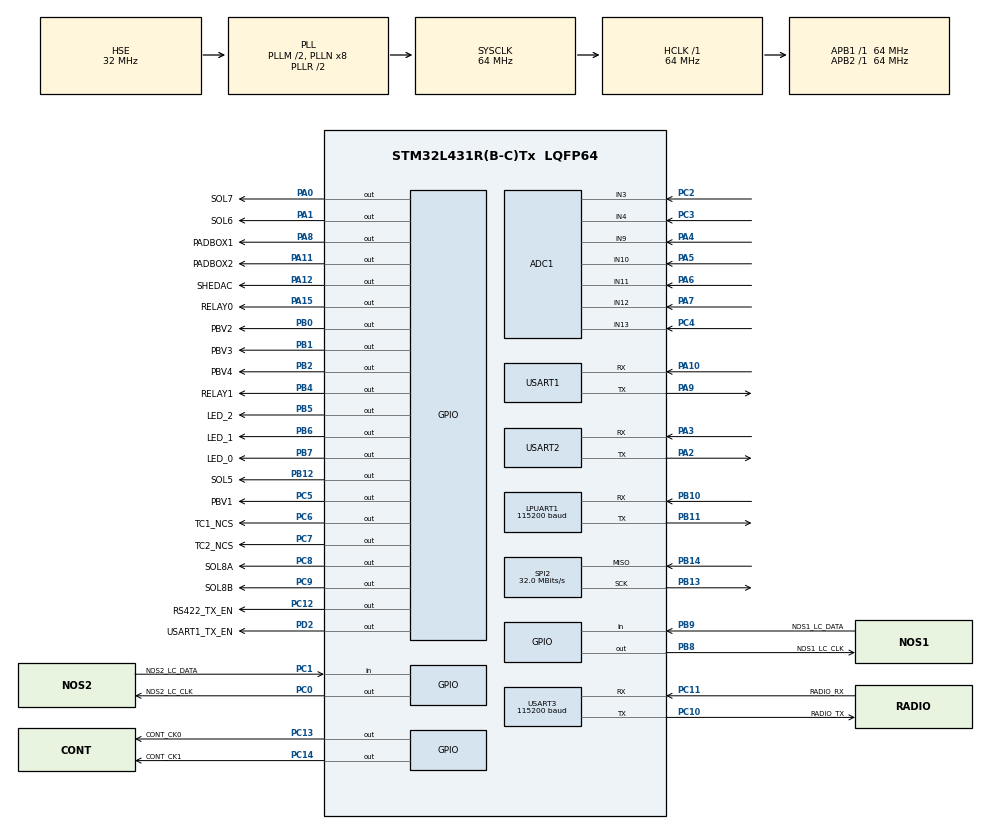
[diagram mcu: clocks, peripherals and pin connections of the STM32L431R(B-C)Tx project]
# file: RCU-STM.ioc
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ADC1.Channel-0\#ChannelRegularConversion=ADC_CHANNEL_13
ADC1.Channel-1\#ChannelRegularConversion=ADC_CHANNEL_10
ADC1.Channel-2\#ChannelRegularConversion=ADC_CHANNEL_9
ADC1.Channel-4\#ChannelRegularConversion=ADC_CHANNEL_3
ADC1.ClockPrescaler=ADC_CLOCK_ASYNC_DIV1
ADC1.ContinuousConvMode=ENABLE
ADC1.NbrOfConversion=4
ADC1.NbrOfConversionFlag=1
ADC1.OffsetNumber-0\#ChannelRegularConversion=ADC_OFFSET_NONE
ADC1.OffsetNumber-1\#ChannelRegularConversion=ADC_OFFSET_NONE
ADC1.OffsetNumber-2\#ChannelRegularConversion=ADC_OFFSET_NONE
ADC1.OffsetNumber-4\#ChannelRegularConversion=ADC_OFFSET_NONE
ADC1.Rank-0\#ChannelRegularConversion=1
ADC1.Rank-1\#ChannelRegularConversion=2
ADC1.Rank-2\#ChannelRegularConversion=3
ADC1.Rank-4\#ChannelRegularConversion=4
ADC1.SamplingTime-0\#ChannelRegularConversion=ADC_SAMPLETIME_247CYCLES_5
ADC1.SamplingTime-1\#ChannelRegularConversion=ADC_SAMPLETIME_247CYCLES_5
ADC1.SamplingTime-2\#ChannelRegularConversion=ADC_SAMPLETIME_247CYCLES_5
ADC1.SamplingTime-4\#ChannelRegularConversion=ADC_SAMPLETIME_247CYCLES_5
ADC1.master=1
FREERTOS.Tasks01=defaultTask,0,128,StartDefaultTask,Default,NULL,Dynamic,NULL,NULL
FREERTOS.configTOTAL_HEAP_SIZE=59936
FREERTOS.configUSE_NEWLIB_REENTRANT=1
FREERTOS.configUSE_TIMERS=1
LPUART1.BaudRate=115200
LPUART1.WordLength=UART_WORDLENGTH_8B
Mcu.Family=STM32L4
Mcu.Name=STM32L431R(B-C)Tx
Mcu.Package=LQFP64
NVIC.LPUART1_IRQn=true\:5\:0\:false\:false\:true\:true\:true\:true\:true
NVIC.PriorityGroup=NVIC_PRIORITYGROUP_4
NVIC.TIM1_UP_TIM16_IRQn=true\:15\:0\:false\:false\:true\:false\:false\:true\:true
NVIC.TimeBase=TIM1_UP_TIM16_IRQn
NVIC.TimeBaseIP=TIM1
NVIC.USART1_IRQn=true\:5\:0\:false\:false\:true\:true\:true\:true\:true
NVIC.USART2_IRQn=true\:5\:0\:false\:false\:true\:true\:true\:true\:true
NVIC.USART3_IRQn=true\:5\:0\:false\:false\:true\:true\:true\:true\:true
PA0.GPIO_Label=SOL7
PA0.PinState=GPIO_PIN_SET
PA0.Signal=GPIO_Output
PA1.GPIO_Label=SOL6
PA1.PinState=GPIO_PIN_SET
PA1.Signal=GPIO_Output
PA10.Mode=Asynchronous
PA10.Signal=USART1_RX
PA11.GPIO_Label=PADBOX2
PA11.PinState=GPIO_PIN_SET
PA11.Signal=GPIO_Output
PA12.GPIO_Label=SHEDAC
PA12.PinState=GPIO_PIN_SET
PA12.Signal=GPIO_Output
PA13\ (JTMS-SWDIO).Mode=Trace_Asynchronous_SW
PA13\ (JTMS-SWDIO).Signal=SYS_JTMS-SWDIO
PA14\ (JTCK-SWCLK).Mode=Trace_Asynchronous_SW
PA14\ (JTCK-SWCLK).Signal=SYS_JTCK-SWCLK
PA15\ (JTDI).GPIO_Label=RELAY0
PA15\ (JTDI).PinState=GPIO_PIN_SET
PA15\ (JTDI).Signal=GPIO_Output
PA2.Mode=Asynchronous
PA2.Signal=USART2_TX
PA3.Mode=Asynchronous
PA3.Signal=USART2_RX
PA4.Signal=ADCx_IN9
PA5.Signal=ADCx_IN10
PA6.Signal=ADCx_IN11
PA7.Signal=ADCx_IN12
PA8.GPIO_Label=PADBOX1
PA8.PinState=GPIO_PIN_SET
PA8.Signal=GPIO_Output
PA9.Mode=Asynchronous
PA9.Signal=USART1_TX
PB0.GPIO_Label=PBV2
PB0.PinState=GPIO_PIN_SET
PB0.Signal=GPIO_Output
PB1.GPIO_Label=PBV3
PB1.PinState=GPIO_PIN_SET
PB1.Signal=GPIO_Output
PB10.Mode=Asynchronous
PB10.Signal=LPUART1_RX
PB11.Mode=Asynchronous
PB11.Signal=LPUART1_TX
PB12.GPIO_Label=SOL5
PB12.PinState=GPIO_PIN_SET
PB12.Signal=GPIO_Output
PB13.Mode=RX_Only_Simplex_Unidirect_Master
PB13.Signal=SPI2_SCK
PB14.Mode=RX_Only_Simplex_Unidirect_Master
PB14.Signal=SPI2_MISO
PB2.GPIO_Label=PBV4
PB2.PinState=GPIO_PIN_RESET
PB2.Signal=GPIO_Output
PB3\ (JTDO-TRACESWO).Mode=Trace_Asynchronous_SW
PB3\ (JTDO-TRACESWO).Signal=SYS_JTDO-SWO
PB4\ (NJTRST).GPIO_Label=RELAY1
PB4\ (NJTRST).PinState=GPIO_PIN_SET
PB4\ (NJTRST).Signal=GPIO_Output
PB5.GPIO_Label=LED_2
PB5.Signal=GPIO_Output
PB6.GPIO_Label=LED_1
PB6.Signal=GPIO_Output
PB7.GPIO_Label=LED_0
PB7.Signal=GPIO_Output
PB8.GPIO_Label=NOS1_LC_CLK
PB8.Signal=GPIO_Output
PB9.GPIO_Label=NOS1_LC_DATA
PB9.Signal=GPIO_Input
PC0.GPIO_Label=NOS2_LC_CLK
PC0.Signal=GPIO_Output
PC1.GPIO_Label=NOS2_LC_DATA
PC1.Signal=GPIO_Input
PC10.GPIO_Label=RADIO_TX
PC10.Mode=Asynchronous
PC10.Signal=USART3_TX
PC11.GPIO_Label=RADIO_RX
PC11.Mode=Asynchronous
PC11.Signal=USART3_RX
PC12.GPIO_Label=RS422_TX_EN
PC12.Signal=GPIO_Output
PC13.GPIO_Label=CONT_CK0
PC13.GPIO_ModeDefaultOutputPP=GPIO_MODE_OUTPUT_PP
PC13.GPIO_PuPd=GPIO_NOPULL
PC13.Signal=GPIO_Output
PC14-OSC32_IN\ (PC14).GPIO_Label=CONT_CK1
PC14-OSC32_IN\ (PC14).Signal=GPIO_Output
PC2.Signal=ADCx_IN3
PC3.Signal=ADCx_IN4
PC4.Signal=ADCx_IN13
PC5.GPIO_Label=PBV1
PC5.PinState=GPIO_PIN_SET
PC5.Signal=GPIO_Output
PC6.GPIO_Label=TC1_NCS
PC6.Signal=GPIO_Output
PC7.GPIO_Label=TC2_NCS
PC7.Signal=GPIO_Output
PC8.GPIO_Label=SOL8A
PC8.PinState=GPIO_PIN_SET
PC8.Signal=GPIO_Output
PC9.GPIO_Label=SOL8B
PC9.PinState=GPIO_PIN_SET
PC9.Signal=GPIO_Output
PD2.GPIO_Label=USART1_TX_EN
PD2.GPIO_PuPd=GPIO_PULLDOWN
PD2.PinState=GPIO_PIN_RESET
PD2.Signal=GPIO_Output
PH0-OSC_IN\ (PH0).Mode=HSE-External-Oscillator
PH0-OSC_IN\ (PH0).Signal=RCC_OSC_IN
PH1-OSC_OUT\ (PH1).Mode=HSE-External-Oscillator
PH1-OSC_OUT\ (PH1).Signal=RCC_OSC_OUT
ProjectManager.HeapSize=0x200
ProjectManager.StackSize=0x400
ProjectManager.TargetToolchain=STM32CubeIDE
RCC.ADCFreq_Value=64000000
RCC.AHBFreq_Value=64000000
RCC.APB1Freq_Value=64000000
RCC.APB1TimFreq_Value=64000000
RCC.APB2Freq_Value=64000000
RCC.APB2TimFreq_Value=64000000
RCC.CortexFreq_Value=64000000
RCC.HCLKFreq_Value=64000000
RCC.HSE_VALUE=32000000
RCC.HSI48_VALUE=48000000
RCC.HSI_VALUE=16000000
RCC.LSE_VALUE=32768
RCC.MSI_VALUE=4000000
RCC.PLLM=2
RCC.PLLSAI1N=16
RCC.PLLSAI1R=RCC_PLLR_DIV4
RCC.PLLSourceVirtual=RCC_PLLSOURCE_HSE
RCC.SYSCLKFreq_VALUE=64000000
RCC.SYSCLKSource=RCC_SYSCLKSOURCE_PLLCLK
RCC.VCOOutputFreq_Value=128000000
SH.ADCx_IN10.0=ADC1_IN10,IN10-Single-Ended
SH.ADCx_IN11.0=ADC1_IN11,IN11-Single-Ended
SH.ADCx_IN12.0=ADC1_IN12,IN12-Single-Ended
SH.ADCx_IN13.0=ADC1_IN13,IN13-Single-Ended
SH.ADCx_IN3.0=ADC1_IN3,IN3-Single-Ended
SH.ADCx_IN4.0=ADC1_IN4,IN4-Single-Ended
SH.ADCx_IN9.0=ADC1_IN9,IN9-Single-Ended
SPI2.BaudRatePrescaler=SPI_BAUDRATEPRESCALER_2
SPI2.CalculateBaudRate=32.0 MBits/s
SPI2.DataSize=SPI_DATASIZE_8BIT
SPI2.Direction=SPI_DIRECTION_2LINES_RXONLY
SPI2.Mode=SPI_MODE_MASTER
SPI2.VirtualType=VM_MASTER
USART1.VirtualMode-Asynchronous=VM_ASYNC
USART2.VirtualMode-Asynchronous=VM_ASYNC
USART3.BaudRate=115200
USART3.VirtualMode-Asynchronous=VM_ASYNC
VP_CRC_VS_CRC.Mode=CRC_Activate
VP_FREERTOS_VS_CMSIS_V1.Mode=CMSIS_V1
VP_SYS_VS_tim1.Mode=TIM1
board=custom

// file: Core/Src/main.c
/* USER CODE BEGIN Header */
/**
  ******************************************************************************
  * @file           : main.c
  * @brief          : Main program body
  ******************************************************************************
  * @attention
  *
  * Copyright (c) 2023 STMicroelectronics.
  * All rights reserved.
  *
  * This software is licensed under terms that can be found in the LICENSE file
  * in the root directory of this software component.
  * If no LICENSE file comes with this software, it is provided AS-IS.
  *
  ******************************************************************************
  */
/* USER CODE END Header */
#include "main.h"
#include "cmsis_os.h"

/* USER CODE BEGIN Includes */
#include "RunInterface.hpp"

/* USER CODE END Includes */

ADC_HandleTypeDef hadc1;

CRC_HandleTypeDef hcrc;

SPI_HandleTypeDef hspi2;

osThreadId defaultTaskHandle;

void SystemClock_Config(void);
static void MX_GPIO_Init(void);
static void MX_ADC1_Init(void);
static void MX_LPUART1_UART_Init(void);
static void MX_USART1_UART_Init(void);
static void MX_USART2_UART_Init(void);
static void MX_USART3_UART_Init(void);
static void MX_SPI2_Init(void);
static void MX_CRC_Init(void);
void StartDefaultTask(void const * argument);

int main(void)
{

  /* MCU Configuration--------------------------------------------------------*/

  /* Reset of all peripherals, Initializes the Flash interface and the Systick. */
  HAL_Init();

  /* Configure the system clock */
  SystemClock_Config();

  /* Initialize all configured peripherals */
  MX_GPIO_Init();
  MX_ADC1_Init();
  MX_LPUART1_UART_Init();
  MX_USART1_UART_Init();
  MX_USART2_UART_Init();
  MX_USART3_UART_Init();
  MX_SPI2_Init();
  MX_CRC_Init();
  /* USER CODE BEGIN 2 */

  run_interface();
#if 0

  /* USER CODE END 2 */

  /* Create the thread(s) */
  /* definition and creation of defaultTask */
  osThreadDef(defaultTask, StartDefaultTask, osPriorityNormal, 0, 128);
  defaultTaskHandle = osThreadCreate(osThread(defaultTask), NULL);

  /* Start scheduler */
  osKernelStart();

  /* We should never get here as control is now taken by the scheduler */
  /* Infinite loop */
  while (1)
  {

    /* USER CODE BEGIN 3 */
  }

#endif
  /* USER CODE END 3 */
}

void SystemClock_Config(void)
{
  RCC_OscInitTypeDef RCC_OscInitStruct = {0};
  RCC_ClkInitTypeDef RCC_ClkInitStruct = {0};

  /** Configure the main internal regulator output voltage
  */
  if (HAL_PWREx_ControlVoltageScaling(PWR_REGULATOR_VOLTAGE_SCALE1) != HAL_OK)
  {
    Error_Handler();
  }

  /** Initializes the RCC Oscillators according to the specified parameters
  * in the RCC_OscInitTypeDef structure.
  */
  RCC_OscInitStruct.OscillatorType = RCC_OSCILLATORTYPE_HSE;
  RCC_OscInitStruct.HSEState = RCC_HSE_ON;
  RCC_OscInitStruct.PLL.PLLState = RCC_PLL_ON;
  RCC_OscInitStruct.PLL.PLLSource = RCC_PLLSOURCE_HSE;
  RCC_OscInitStruct.PLL.PLLM = 2;
  RCC_OscInitStruct.PLL.PLLN = 8;
  RCC_OscInitStruct.PLL.PLLP = RCC_PLLP_DIV7;
  RCC_OscInitStruct.PLL.PLLQ = RCC_PLLQ_DIV2;
  RCC_OscInitStruct.PLL.PLLR = RCC_PLLR_DIV2;
  if (HAL_RCC_OscConfig(&RCC_OscInitStruct) != HAL_OK)
  {
    Error_Handler();
  }

  /** Initializes the CPU, AHB and APB buses clocks
  */
  RCC_ClkInitStruct.ClockType = RCC_CLOCKTYPE_HCLK|RCC_CLOCKTYPE_SYSCLK
                              |RCC_CLOCKTYPE_PCLK1|RCC_CLOCKTYPE_PCLK2;
  RCC_ClkInitStruct.SYSCLKSource = RCC_SYSCLKSOURCE_PLLCLK;
  RCC_ClkInitStruct.AHBCLKDivider = RCC_SYSCLK_DIV1;
  RCC_ClkInitStruct.APB1CLKDivider = RCC_HCLK_DIV1;
  RCC_ClkInitStruct.APB2CLKDivider = RCC_HCLK_DIV1;

  if (HAL_RCC_ClockConfig(&RCC_ClkInitStruct, FLASH_LATENCY_3) != HAL_OK)
  {
    Error_Handler();
  }
}

static void MX_ADC1_Init(void)
{

  ADC_ChannelConfTypeDef sConfig = {0};

  /** Common config
  */
  hadc1.Instance = ADC1;
  hadc1.Init.ClockPrescaler = ADC_CLOCK_ASYNC_DIV1;
  hadc1.Init.Resolution = ADC_RESOLUTION_12B;
  hadc1.Init.DataAlign = ADC_DATAALIGN_RIGHT;
  hadc1.Init.ScanConvMode = ADC_SCAN_ENABLE;
  hadc1.Init.EOCSelection = ADC_EOC_SINGLE_CONV;
  hadc1.Init.LowPowerAutoWait = DISABLE;
  hadc1.Init.ContinuousConvMode = ENABLE;
  hadc1.Init.NbrOfConversion = 4;
  hadc1.Init.DiscontinuousConvMode = DISABLE;
  hadc1.Init.ExternalTrigConv = ADC_SOFTWARE_START;
  hadc1.Init.ExternalTrigConvEdge = ADC_EXTERNALTRIGCONVEDGE_NONE;
  hadc1.Init.DMAContinuousRequests = DISABLE;
  hadc1.Init.Overrun = ADC_OVR_DATA_PRESERVED;
  hadc1.Init.OversamplingMode = DISABLE;
  if (HAL_ADC_Init(&hadc1) != HAL_OK)
  {
    Error_Handler();
  }

  /** Configure Regular Channel
  */
  sConfig.Channel = ADC_CHANNEL_13;
  sConfig.Rank = ADC_REGULAR_RANK_1;
  sConfig.SamplingTime = ADC_SAMPLETIME_247CYCLES_5;
  sConfig.SingleDiff = ADC_SINGLE_ENDED;
  sConfig.OffsetNumber = ADC_OFFSET_NONE;
  sConfig.Offset = 0;
  if (HAL_ADC_ConfigChannel(&hadc1, &sConfig) != HAL_OK)
  {
    Error_Handler();
  }

  /** Configure Regular Channel
  */
  sConfig.Channel = ADC_CHANNEL_10;
  sConfig.Rank = ADC_REGULAR_RANK_2;
  if (HAL_ADC_ConfigChannel(&hadc1, &sConfig) != HAL_OK)
  {
    Error_Handler();
  }

  /** Configure Regular Channel
  */
  sConfig.Channel = ADC_CHANNEL_9;
  sConfig.Rank = ADC_REGULAR_RANK_3;
  if (HAL_ADC_ConfigChannel(&hadc1, &sConfig) != HAL_OK)
  {
    Error_Handler();
  }

  /** Configure Regular Channel
  */
  sConfig.Channel = ADC_CHANNEL_3;
  sConfig.Rank = ADC_REGULAR_RANK_4;
  if (HAL_ADC_ConfigChannel(&hadc1, &sConfig) != HAL_OK)
  {
    Error_Handler();
  }
  /* USER CODE BEGIN ADC1_Init 2 */
  sConfig.Rank = ADC_REGULAR_RANK_1;

  /* USER CODE END ADC1_Init 2 */

}

static void MX_CRC_Init(void)
{

  hcrc.Instance = CRC;
  hcrc.Init.DefaultPolynomialUse = DEFAULT_POLYNOMIAL_ENABLE;
  hcrc.Init.DefaultInitValueUse = DEFAULT_INIT_VALUE_ENABLE;
  hcrc.Init.InputDataInversionMode = CRC_INPUTDATA_INVERSION_NONE;
  hcrc.Init.OutputDataInversionMode = CRC_OUTPUTDATA_INVERSION_DISABLE;
  hcrc.InputDataFormat = CRC_INPUTDATA_FORMAT_BYTES;
  if (HAL_CRC_Init(&hcrc) != HAL_OK)
  {
    Error_Handler();
  }

}

static void MX_LPUART1_UART_Init(void)
{

  LL_LPUART_InitTypeDef LPUART_InitStruct = {0};

  LL_GPIO_InitTypeDef GPIO_InitStruct = {0};
  RCC_PeriphCLKInitTypeDef PeriphClkInit = {0};

  /** Initializes the peripherals clock
  */
  PeriphClkInit.PeriphClockSelection = RCC_PERIPHCLK_LPUART1;
  PeriphClkInit.Lpuart1ClockSelection = RCC_LPUART1CLKSOURCE_PCLK1;
  if (HAL_RCCEx_PeriphCLKConfig(&PeriphClkInit) != HAL_OK)
  {
    Error_Handler();
  }

  /* Peripheral clock enable */
  LL_APB1_GRP2_EnableClock(LL_APB1_GRP2_PERIPH_LPUART1);

  LL_AHB2_GRP1_EnableClock(LL_AHB2_GRP1_PERIPH_GPIOB);
  /**LPUART1 GPIO Configuration
  PB10   ------> LPUART1_RX
  PB11   ------> LPUART1_TX
  */
  GPIO_InitStruct.Pin = LL_GPIO_PIN_10|LL_GPIO_PIN_11;
  GPIO_InitStruct.Mode = LL_GPIO_MODE_ALTERNATE;
  GPIO_InitStruct.Speed = LL_GPIO_SPEED_FREQ_VERY_HIGH;
  GPIO_InitStruct.OutputType = LL_GPIO_OUTPUT_PUSHPULL;
  GPIO_InitStruct.Pull = LL_GPIO_PULL_NO;
  GPIO_InitStruct.Alternate = LL_GPIO_AF_8;
  LL_GPIO_Init(GPIOB, &GPIO_InitStruct);

  /* LPUART1 interrupt Init */
  NVIC_SetPriority(LPUART1_IRQn, NVIC_EncodePriority(NVIC_GetPriorityGrouping(),5, 0));
  NVIC_EnableIRQ(LPUART1_IRQn);

  LPUART_InitStruct.BaudRate = 115200;
  LPUART_InitStruct.DataWidth = LL_LPUART_DATAWIDTH_8B;
  LPUART_InitStruct.StopBits = LL_LPUART_STOPBITS_1;
  LPUART_InitStruct.Parity = LL_LPUART_PARITY_NONE;
  LPUART_InitStruct.TransferDirection = LL_LPUART_DIRECTION_TX_RX;
  LPUART_InitStruct.HardwareFlowControl = LL_LPUART_HWCONTROL_NONE;
  LL_LPUART_Init(LPUART1, &LPUART_InitStruct);
  LL_LPUART_Enable(LPUART1);

}

static void MX_USART1_UART_Init(void)
{

  LL_USART_InitTypeDef USART_InitStruct = {0};

  LL_GPIO_InitTypeDef GPIO_InitStruct = {0};
  RCC_PeriphCLKInitTypeDef PeriphClkInit = {0};

  /** Initializes the peripherals clock
  */
  PeriphClkInit.PeriphClockSelection = RCC_PERIPHCLK_USART1;
  PeriphClkInit.Usart1ClockSelection = RCC_USART1CLKSOURCE_PCLK2;
  if (HAL_RCCEx_PeriphCLKConfig(&PeriphClkInit) != HAL_OK)
  {
    Error_Handler();
  }

  /* Peripheral clock enable */
  LL_APB2_GRP1_EnableClock(LL_APB2_GRP1_PERIPH_USART1);

  LL_AHB2_GRP1_EnableClock(LL_AHB2_GRP1_PERIPH_GPIOA);
  /**USART1 GPIO Configuration
  PA9   ------> USART1_TX
  PA10   ------> USART1_RX
  */
  GPIO_InitStruct.Pin = LL_GPIO_PIN_9|LL_GPIO_PIN_10;
  GPIO_InitStruct.Mode = LL_GPIO_MODE_ALTERNATE;
  GPIO_InitStruct.Speed = LL_GPIO_SPEED_FREQ_VERY_HIGH;
  GPIO_InitStruct.OutputType = LL_GPIO_OUTPUT_PUSHPULL;
  GPIO_InitStruct.Pull = LL_GPIO_PULL_NO;
  GPIO_InitStruct.Alternate = LL_GPIO_AF_7;
  LL_GPIO_Init(GPIOA, &GPIO_InitStruct);

  /* USART1 interrupt Init */
  NVIC_SetPriority(USART1_IRQn, NVIC_EncodePriority(NVIC_GetPriorityGrouping(),5, 0));
  NVIC_EnableIRQ(USART1_IRQn);

  USART_InitStruct.BaudRate = 115200;
  USART_InitStruct.DataWidth = LL_USART_DATAWIDTH_8B;
  USART_InitStruct.StopBits = LL_USART_STOPBITS_1;
  USART_InitStruct.Parity = LL_USART_PARITY_NONE;
  USART_InitStruct.TransferDirection = LL_USART_DIRECTION_TX_RX;
  USART_InitStruct.HardwareFlowControl = LL_USART_HWCONTROL_NONE;
  USART_InitStruct.OverSampling = LL_USART_OVERSAMPLING_16;
  LL_USART_Init(USART1, &USART_InitStruct);
  LL_USART_ConfigAsyncMode(USART1);
  LL_USART_Enable(USART1);

}

static void MX_USART2_UART_Init(void)
{

  LL_USART_InitTypeDef USART_InitStruct = {0};

  LL_GPIO_InitTypeDef GPIO_InitStruct = {0};
  RCC_PeriphCLKInitTypeDef PeriphClkInit = {0};

  /** Initializes the peripherals clock
  */
  PeriphClkInit.PeriphClockSelection = RCC_PERIPHCLK_USART2;
  PeriphClkInit.Usart2ClockSelection = RCC_USART2CLKSOURCE_PCLK1;
  if (HAL_RCCEx_PeriphCLKConfig(&PeriphClkInit) != HAL_OK)
  {
    Error_Handler();
  }

  /* Peripheral clock enable */
  LL_APB1_GRP1_EnableClock(LL_APB1_GRP1_PERIPH_USART2);

  LL_AHB2_GRP1_EnableClock(LL_AHB2_GRP1_PERIPH_GPIOA);
  /**USART2 GPIO Configuration
  PA2   ------> USART2_TX
  PA3   ------> USART2_RX
  */
  GPIO_InitStruct.Pin = LL_GPIO_PIN_2|LL_GPIO_PIN_3;
  GPIO_InitStruct.Mode = LL_GPIO_MODE_ALTERNATE;
  GPIO_InitStruct.Speed = LL_GPIO_SPEED_FREQ_VERY_HIGH;
  GPIO_InitStruct.OutputType = LL_GPIO_OUTPUT_PUSHPULL;
  GPIO_InitStruct.Pull = LL_GPIO_PULL_NO;
  GPIO_InitStruct.Alternate = LL_GPIO_AF_7;
  LL_GPIO_Init(GPIOA, &GPIO_InitStruct);

  /* USART2 interrupt Init */
  NVIC_SetPriority(USART2_IRQn, NVIC_EncodePriority(NVIC_GetPriorityGrouping(),5, 0));
  NVIC_EnableIRQ(USART2_IRQn);

  USART_InitStruct.BaudRate = 115200;
  USART_InitStruct.DataWidth = LL_USART_DATAWIDTH_8B;
  USART_InitStruct.StopBits = LL_USART_STOPBITS_1;
  USART_InitStruct.Parity = LL_USART_PARITY_NONE;
  USART_InitStruct.TransferDirection = LL_USART_DIRECTION_TX_RX;
  USART_InitStruct.HardwareFlowControl = LL_USART_HWCONTROL_NONE;
  USART_InitStruct.OverSampling = LL_USART_OVERSAMPLING_16;
  LL_USART_Init(USART2, &USART_InitStruct);
  LL_USART_ConfigAsyncMode(USART2);
  LL_USART_Enable(USART2);

}

static void MX_USART3_UART_Init(void)
{

  LL_USART_InitTypeDef USART_InitStruct = {0};

  LL_GPIO_InitTypeDef GPIO_InitStruct = {0};
  RCC_PeriphCLKInitTypeDef PeriphClkInit = {0};

  /** Initializes the peripherals clock
  */
  PeriphClkInit.PeriphClockSelection = RCC_PERIPHCLK_USART3;
  PeriphClkInit.Usart3ClockSelection = RCC_USART3CLKSOURCE_PCLK1;
  if (HAL_RCCEx_PeriphCLKConfig(&PeriphClkInit) != HAL_OK)
  {
    Error_Handler();
  }

  /* Peripheral clock enable */
  LL_APB1_GRP1_EnableClock(LL_APB1_GRP1_PERIPH_USART3);

  LL_AHB2_GRP1_EnableClock(LL_AHB2_GRP1_PERIPH_GPIOC);
  /**USART3 GPIO Configuration
  PC10   ------> USART3_TX
  PC11   ------> USART3_RX
  */
  GPIO_InitStruct.Pin = LL_GPIO_PIN_10|LL_GPIO_PIN_11;
  GPIO_InitStruct.Mode = LL_GPIO_MODE_ALTERNATE;
  GPIO_InitStruct.Speed = LL_GPIO_SPEED_FREQ_VERY_HIGH;
  GPIO_InitStruct.OutputType = LL_GPIO_OUTPUT_PUSHPULL;
  GPIO_InitStruct.Pull = LL_GPIO_PULL_NO;
  GPIO_InitStruct.Alternate = LL_GPIO_AF_7;
  LL_GPIO_Init(GPIOC, &GPIO_InitStruct);

  /* USART3 interrupt Init */
  NVIC_SetPriority(USART3_IRQn, NVIC_EncodePriority(NVIC_GetPriorityGrouping(),5, 0));
  NVIC_EnableIRQ(USART3_IRQn);

  USART_InitStruct.BaudRate = 115200;
  USART_InitStruct.DataWidth = LL_USART_DATAWIDTH_8B;
  USART_InitStruct.StopBits = LL_USART_STOPBITS_1;
  USART_InitStruct.Parity = LL_USART_PARITY_NONE;
  USART_InitStruct.TransferDirection = LL_USART_DIRECTION_TX_RX;
  USART_InitStruct.HardwareFlowControl = LL_USART_HWCONTROL_NONE;
  USART_InitStruct.OverSampling = LL_USART_OVERSAMPLING_16;
  LL_USART_Init(USART3, &USART_InitStruct);
  LL_USART_ConfigAsyncMode(USART3);
  LL_USART_Enable(USART3);

}

static void MX_SPI2_Init(void)
{

  /* SPI2 parameter configuration*/
  hspi2.Instance = SPI2;
  hspi2.Init.Mode = SPI_MODE_MASTER;
  hspi2.Init.Direction = SPI_DIRECTION_2LINES_RXONLY;
  hspi2.Init.DataSize = SPI_DATASIZE_8BIT;
  hspi2.Init.CLKPolarity = SPI_POLARITY_LOW;
  hspi2.Init.CLKPhase = SPI_PHASE_1EDGE;
  hspi2.Init.NSS = SPI_NSS_SOFT;
  hspi2.Init.BaudRatePrescaler = SPI_BAUDRATEPRESCALER_2;
  hspi2.Init.FirstBit = SPI_FIRSTBIT_MSB;
  hspi2.Init.TIMode = SPI_TIMODE_DISABLE;
  hspi2.Init.CRCCalculation = SPI_CRCCALCULATION_DISABLE;
  hspi2.Init.CRCPolynomial = 7;
  hspi2.Init.CRCLength = SPI_CRC_LENGTH_DATASIZE;
  hspi2.Init.NSSPMode = SPI_NSS_PULSE_ENABLE;
  if (HAL_SPI_Init(&hspi2) != HAL_OK)
  {
    Error_Handler();
  }

}

static void MX_GPIO_Init(void)
{
  GPIO_InitTypeDef GPIO_InitStruct = {0};

  /* GPIO Ports Clock Enable */
  __HAL_RCC_GPIOC_CLK_ENABLE();
  __HAL_RCC_GPIOH_CLK_ENABLE();
  __HAL_RCC_GPIOA_CLK_ENABLE();
  __HAL_RCC_GPIOB_CLK_ENABLE();
  __HAL_RCC_GPIOD_CLK_ENABLE();

  /*Configure GPIO pin Output Level */
  HAL_GPIO_WritePin(GPIOC, CONT_CK0_Pin|CONT_CK1_Pin|NOS2_LC_CLK_Pin|TC1_NCS_Pin
                          |TC2_NCS_Pin|RS422_TX_EN_Pin, GPIO_PIN_RESET);

  /*Configure GPIO pin Output Level */
  HAL_GPIO_WritePin(GPIOA, SOL7_Pin|SOL6_Pin|PADBOX1_Pin|PADBOX2_Pin
                          |SHEDAC_Pin|RELAY0_Pin, GPIO_PIN_SET);

  /*Configure GPIO pin Output Level */
  HAL_GPIO_WritePin(GPIOC, PBV1_Pin|SOL8A_Pin|SOL8B_Pin, GPIO_PIN_SET);

  /*Configure GPIO pin Output Level */
  HAL_GPIO_WritePin(GPIOB, PBV2_Pin|PBV3_Pin|SOL5_Pin|RELAY1_Pin, GPIO_PIN_SET);

  /*Configure GPIO pin Output Level */
  HAL_GPIO_WritePin(GPIOB, PBV4_Pin|LED_2_Pin|LED_1_Pin|LED_0_Pin
                          |NOS1_LC_CLK_Pin, GPIO_PIN_RESET);

  /*Configure GPIO pin Output Level */
  HAL_GPIO_WritePin(USART1_TX_EN_GPIO_Port, USART1_TX_EN_Pin, GPIO_PIN_RESET);

  /*Configure GPIO pins : CONT_CK0_Pin CONT_CK1_Pin NOS2_LC_CLK_Pin PBV1_Pin
                           TC1_NCS_Pin TC2_NCS_Pin SOL8A_Pin SOL8B_Pin
                           RS422_TX_EN_Pin */
  GPIO_InitStruct.Pin = CONT_CK0_Pin|CONT_CK1_Pin|NOS2_LC_CLK_Pin|PBV1_Pin
                          |TC1_NCS_Pin|TC2_NCS_Pin|SOL8A_Pin|SOL8B_Pin
                          |RS422_TX_EN_Pin;
  GPIO_InitStruct.Mode = GPIO_MODE_OUTPUT_PP;
  GPIO_InitStruct.Pull = GPIO_NOPULL;
  GPIO_InitStruct.Speed = GPIO_SPEED_FREQ_LOW;
  HAL_GPIO_Init(GPIOC, &GPIO_InitStruct);

  /*Configure GPIO pin : NOS2_LC_DATA_Pin */
  GPIO_InitStruct.Pin = NOS2_LC_DATA_Pin;
  GPIO_InitStruct.Mode = GPIO_MODE_INPUT;
  GPIO_InitStruct.Pull = GPIO_NOPULL;
  HAL_GPIO_Init(NOS2_LC_DATA_GPIO_Port, &GPIO_InitStruct);

  /*Configure GPIO pins : SOL7_Pin SOL6_Pin PADBOX1_Pin PADBOX2_Pin
                           SHEDAC_Pin RELAY0_Pin */
  GPIO_InitStruct.Pin = SOL7_Pin|SOL6_Pin|PADBOX1_Pin|PADBOX2_Pin
                          |SHEDAC_Pin|RELAY0_Pin;
  GPIO_InitStruct.Mode = GPIO_MODE_OUTPUT_PP;
  GPIO_InitStruct.Pull = GPIO_NOPULL;
  GPIO_InitStruct.Speed = GPIO_SPEED_FREQ_LOW;
  HAL_GPIO_Init(GPIOA, &GPIO_InitStruct);

  /*Configure GPIO pins : PBV2_Pin PBV3_Pin PBV4_Pin SOL5_Pin
                           RELAY1_Pin LED_2_Pin LED_1_Pin LED_0_Pin
                           NOS1_LC_CLK_Pin */
  GPIO_InitStruct.Pin = PBV2_Pin|PBV3_Pin|PBV4_Pin|SOL5_Pin
                          |RELAY1_Pin|LED_2_Pin|LED_1_Pin|LED_0_Pin
                          |NOS1_LC_CLK_Pin;
  GPIO_InitStruct.Mode = GPIO_MODE_OUTPUT_PP;
  GPIO_InitStruct.Pull = GPIO_NOPULL;
  GPIO_InitStruct.Speed = GPIO_SPEED_FREQ_LOW;
  HAL_GPIO_Init(GPIOB, &GPIO_InitStruct);

  /*Configure GPIO pin : USART1_TX_EN_Pin */
  GPIO_InitStruct.Pin = USART1_TX_EN_Pin;
  GPIO_InitStruct.Mode = GPIO_MODE_OUTPUT_PP;
  GPIO_InitStruct.Pull = GPIO_PULLDOWN;
  GPIO_InitStruct.Speed = GPIO_SPEED_FREQ_LOW;
  HAL_GPIO_Init(USART1_TX_EN_GPIO_Port, &GPIO_InitStruct);

  /*Configure GPIO pin : NOS1_LC_DATA_Pin */
  GPIO_InitStruct.Pin = NOS1_LC_DATA_Pin;
  GPIO_InitStruct.Mode = GPIO_MODE_INPUT;
  GPIO_InitStruct.Pull = GPIO_NOPULL;
  HAL_GPIO_Init(NOS1_LC_DATA_GPIO_Port, &GPIO_InitStruct);

}

void StartDefaultTask(void const * argument)
{
}

void HAL_TIM_PeriodElapsedCallback(TIM_HandleTypeDef *htim)
{
  if (htim->Instance == TIM1) {
    HAL_IncTick();
  }
}

void Error_Handler(void)
{
  __disable_irq();
  while (1)
  {
  }
}
